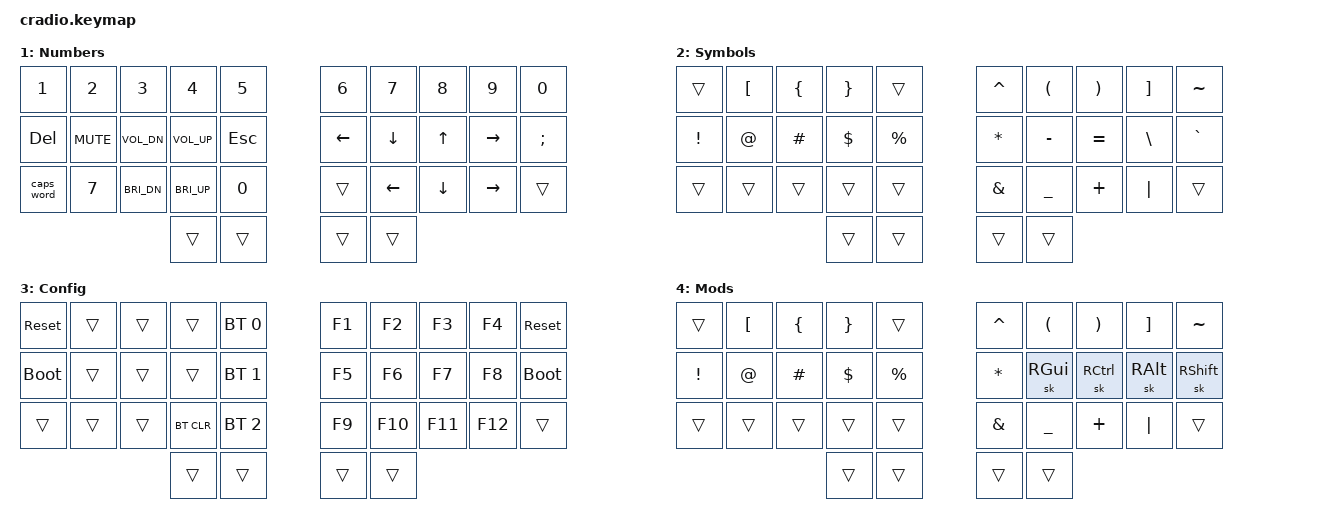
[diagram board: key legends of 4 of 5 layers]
// Copyright (c) 2022 The ZMK Contributors
// SPDX-License-Identifier: MIT

#include <behaviors.dtsi>
#include <dt-bindings/zmk/keys.h>
#include <dt-bindings/zmk/bt.h>

#define HRML(k1,k2,k3,k4) &kp k1  &ht LALT k2  &ht LCTRL k3  &ht LGUI k4 
#define HRMR(k1,k2,k3,k4) &ht RGUI k1  &ht RCTRL k2  &ht RALT k3  &kp k4

&lt {
    flavor = "tap-preferred";
    tapping-term-ms = <250>;
    quick-tap-ms = <180>;
    require-prior-idle-ms = <100>;
};

&sk {
    release-after-ms = <2000>;
    quick-release;
};

/ {
    behaviors {
        ht: hold_tap {
            compatible = "zmk,behavior-hold-tap";
            #binding-cells = <2>;
            flavor = "tap-preferred";
            tapping-term-ms = <280>;
            quick-tap-ms = <180>;
            require-prior-idle-ms = <125>;
            bindings = <&kp>, <&kp>;
        };
        tog_on: toggle_layer_on_only {
            compatible = "zmk,behavior-toggle-layer";
            #binding-cells = <1>;
            display-name = "Toggle Layer On";
            toggle-mode = "on";
        };
        
        caps_word: caps_word {
            compatible = "zmk,behavior-caps-word";
            #binding-cells = <0>;
        };
    };

    conditional_layers {
        compatible = "zmk,conditional-layers";
        tri_layer {
            if-layers = <1 2>;
            then-layer = <3>;
        };
    };

    combos {
        compatible = "zmk,combos";
        combo_esc {
            timeout-ms = <30>;
            key-positions = <12 13>;
            bindings = <&kp ESC>;
        };
        combo_tab {
            timeout-ms = <30>;
            key-positions = <16 17>;
            bindings = <&kp TAB>;
        };
        combo_semi {
            timeout-ms = <30>;
            key-positions = <27 28>;
            bindings = <&kp SEMI>;
        };
        combo_mod {
            timeout-ms = <30>;
            key-positions = <16 17 18>;
            bindings = <&tog 4>;
        };
    };

    keymap {
        compatible = "zmk,keymap";
        default_layer {
            display-name = "Base";
            bindings = <
        //╭──────────┬──────────┬──────────┬──────────┬──────────╮   ╭──────────┬──────────┬──────────┬──────────┬──────────╮
        //│  Q       │  W       │  E       │  R       │  T       │   │  Y       │  U       │  I       │  O       │  P       │
            &kp Q      &kp W      &kp E      &kp R      &kp T          &kp Y      &kp U      &kp K      &kp O      &kp P
        //├──────────┼──────────┼──────────┼──────────┼──────────┤   ├──────────┼──────────┼──────────┼──────────┼──────────┤
        //│  A       │  S       │  D       │  F       │  G       │   │  H       │  J       │  K       │  L       │ ' "      │
            HRML(A,        S,         D,         F)     &kp G          &kp H      HRMR(J,        K,         L,        SQT)
        //├──────────┼──────────┼──────────┼──────────┼──────────┤   ├──────────┼──────────┼──────────┼──────────┼──────────┤
        //│  Z       │  X       │  C       │  V       │  B       │   │  N       │  M       │ , <      │ . >      │ / ?      │
            &kp Z      &kp X      &kp C      &kp V      &kp B          &kp N      &kp M      &kp COMMA  &kp DOT    &kp FSLH
        //╰──────────┴──────────┴──────────┼──────────┼──────────┤   ├──────────┼──────────┼──────────┴──────────┴──────────╯
                                             &sk LSHFT  &lt 2 ENTER   &lt 1 SPACE &kp BSPC
        //                                 ╰──────────┴──────────╯   ╰──────────┴──────────╯
            >;
        };

        right_layer {
            display-name = "Numbers";
            bindings = <
            &kp N1    &kp N2    &kp N3    &kp N4    &kp N5     &kp N6    &kp N7    &kp N8    &kp N9    &kp N0
            &kp DEL   &kp C_MUTE &kp C_VOL_DN &kp C_VOL_UP &kp ESC   &kp LEFT  &kp DOWN  &kp UP    &kp RIGHT &kp SEMI
            &caps_word &kp N7    &kp C_BRI_DN &kp C_BRI_UP &kp N0    &trans    &kp LEFT  &kp DOWN  &kp RIGHT &trans
                                        &trans     &trans        &trans     &trans
            >;
        };

        left_layer {
            display-name = "Symbols";
            bindings = <
            &trans   &kp LBKT  &kp LBRC  &kp RBRC  &trans     &kp CARET &kp LPAR  &kp RPAR  &kp RBKT  &kp TILDE
            &kp EXCL &kp AT    &kp HASH  &kp DLLR  &kp PRCNT  &kp ASTRK &kp MINUS &kp EQUAL &kp BSLH  &kp GRAVE
            &trans   &trans    &trans    &trans    &trans     &kp AMPS  &kp UNDER &kp PLUS  &kp PIPE  &trans
                                        &trans     &trans        &trans     &trans
            >;
        };

        tri_layer {
            display-name = "Config";
            bindings = <
            &sys_reset &trans     &trans     &trans     &bt BT_SEL 0   &kp F1    &kp F2    &kp F3    &kp F4    &sys_reset
            &bootloader &trans   &trans     &trans     &bt BT_SEL 1   &kp F5    &kp F6    &kp F7    &kp F8    &bootloader
            &trans     &trans     &trans     &bt BT_CLR &bt BT_SEL 2   &kp F9    &kp F10   &kp F11   &kp F12   &trans
                                        &trans     &trans        &trans     &trans
            >;
        };

        mod_layer {
            display-name = "Mods";
            bindings = <
            &trans   &kp LBKT  &kp LBRC  &kp RBRC  &trans     &kp CARET &kp LPAR  &kp RPAR  &kp RBKT  &kp TILDE
            &kp EXCL &kp AT    &kp HASH  &kp DLLR  &kp PRCNT  &kp ASTRK &sk RGUI  &sk RCTRL &sk RALT  &sk RSHFT
            &trans   &trans    &trans    &trans    &trans     &kp AMPS  &kp UNDER &kp PLUS  &kp PIPE  &trans
                                        &trans     &trans        &trans     &trans
            >;
        };
    };
};

